# TZ10xx register map
File version: 0.1g
Registers are 32-bit, read-write, reset 0x0 unless marked. A register's access mark holds for its fields unless they carry their own. Offsets are from the block's base; [hi:lo] are bit positions.

## tmr
Base 0x40042000
0x00 TIMER0LOAD
  [31:0] Load — Initial or reload value of the counter (0x00000001 to 0xFFFFFFFF settable) The 0x00000000 setting does not operate the counter. Setting any numeric value other than that enables counting. (Note) Writing to this register writes the same value to Timer0BGLoad.
0x04 TIMER0VALUE ro reset 0xFFFFFFFF — Timer0 Current value Register
  [31:0] value — Count value of the counter at the current time
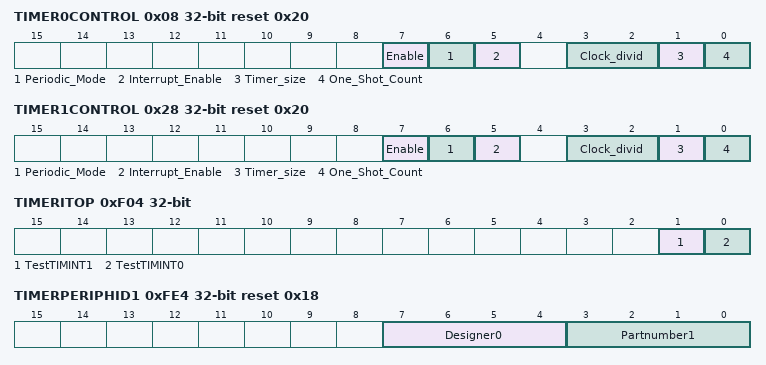
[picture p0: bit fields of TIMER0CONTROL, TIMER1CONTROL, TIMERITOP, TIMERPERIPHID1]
0x08 TIMER0CONTROL reset 0x20
  [7] Enable — Timer operation control 1: Enable 0: Disable
  [6] Periodic_Mode — Timer operation mode 1: Periodic Timer (periodic timer) 0: Free-run Timer (free-run timer)
  [5] Interrupt_Enable — Interrupt control 1: Interrupt enable 0: Interrupt disable
  [3:2] Clock_divid — Prescaler (clock frequency division) 0x3: Reserved 0x2: 1/256 frequency division 0x1: 1/16 frequency division 0x0: No frequency division (same magnification)
  [1] Timer_size — Timer size selection 0x1: Operation as a 32-bit timer 0x0: Operation as a 16-bit timer (high-order bits not used)
  [0] One_Shot_Count — Timer wrapping/one-shot selection 1: One-shot (only one time) 0: Wrapping (repetition)
0x0C TIMER0INTCLR — Timer0 Interrupt clear Register
  [31:0] IntClr — Interrupt clear After the TIMINT0 interrupt occurs, it can be cleared by write access to this register.
0x10 TIMER0RIS ro — Timer0 Raw Interrupt Status Register
  [0] RIS — A timer interrupt (TIMINT0) before masking is occurring. (The interrupt occurs when the counter becomes 0x00000000.) 1: Interrupt request available 0: No interrupt request
0x14 TIMER0MIS ro — Timer0 Masked Interrupt Status Register
  [0] MIS — A timer interrupt (TIMINT0) after masking is occurring. 1: Interrupt request available 0: No interrupt request
0x18 TIMER0BGLOAD — Timer0 BackGround Load Register
  [31:0] BGLoad — Background Load register A count value set in this register is reloaded after the counter becomes 0x00000000 (terminal count). The count value to be reloaded can be changed safely during counting. (Note) Writing to this register does not allow writing to Timer0Load.
0x20 TIMER1LOAD
  [31:0] Load — Initial or reload value of the counter
0x24 TIMER1VALUE ro reset 0xFFFFFFFF — Timer1 Current value Register
  [31:0] value — Count value of the counter at the current time
0x28 TIMER1CONTROL reset 0x20
  [7] Enable — Timer operation control
  [6] Periodic_Mode — Timer operation mode
  [5] Interrupt_Enable — Interrupt control
  [3:2] Clock_divid — Prescaler (clock frequency division)
  [1] Timer_size — Timer size selection
  [0] One_Shot_Count — Selection of timer wrapping and one-shot
0x2C TIMER1INTCLR — Timer1 Interrupt clear Register
  [31:0] IntClr — Interrupt clear
0x30 TIMER1RIS ro — Timer1 Raw Interrupt Status Register
  [0] RIS — A timer interrupt (TIMINT1) after masking is occurring. (The interrupt occurs when the counter becomes 0x00000000.)
0x34 TIMER1MIS ro — Timer1 Masked Interrupt Status Register
  [0] MIS — A timer interrupt (TIMINT1) after masking is occurring.
0x38 TIMER1BGLOAD — Timer1 BackGround Load Register
  [31:0] BGLoad — Background load register
0xF00 TIMERITCR — Timer Integration test control Register
  [0] Test_Mode_Enable — Test mode control 1: Test mode status 0: Normal operation status
0xF04 TIMERITOP — Timer Integration test output set Register
  [1] TestTIMINT1 — Outputs the TIMINT1 signal (only in test mode, write-only) 1: TIMINT1="1" 0: TIMINT1="0" If this register is read, the TMR_TIMERITCR value appears.
  [0] TestTIMINT0 — Outputs the TIMINT0 signal (only in test mode, write-only) 1: TIMINT0="1" 0: TIMINT0="0" If this register is read, the TMR_TIMERITCR value appears.
0xFE0 TIMERPERIPHID0 ro reset 0x4 — Timer Peripheral ID0 Register
  [7:0] Partnumber0 — Peripheral ID (this register stores a value from a hardware viewpoint.) Partnumber(Lower) 804=>04
0xFE4 TIMERPERIPHID1 ro reset 0x18 — Timer Peripheral ID1 Register
  [7:4] Designer0 — Peripheral ID (this register stores a value from a hardware viewpoint.) Designer(Lower) 41=>1
  [3:0] Partnumber1 — Peripheral ID (this register stores a value from a hardware viewpoint.) Partnumber(Lower) 804=>8
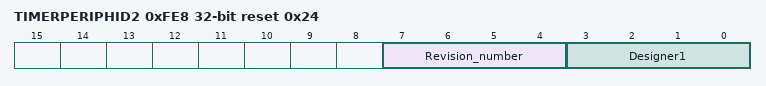
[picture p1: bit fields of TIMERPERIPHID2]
0xFE8 TIMERPERIPHID2 ro reset 0x24 — Timer Peripheral ID2 Register
  [7:4] Revision_number — Peripheral ID (this register stores a value from a hardware viewpoint.) Revision: 1st=>1
  [3:0] Designer1 — Peripheral ID (this register stores a value from a hardware viewpoint.) Designer(Upper) 41=>4
0xFEC TIMERPERIPHID3 ro — Timer Peripheral ID3 Register
  [7:0] Configuration — Peripheral ID (this register stores a value from a hardware viewpoint.) Configuration: 00
0xFF0 TIMERPCELLID0 ro reset 0xD — Timer PrimeCell ID0 Register
  [7:0] TimerPCellID0 — Peripheral ID (this register stores a value from a hardware viewpoint.)
0xFF4 TIMERPCELLID1 ro reset 0xF0 — Timer PrimeCell ID1 Register
  [7:0] TimerPCellID1 — Peripheral ID (this register stores a value from a hardware viewpoint.)
0xFF8 TIMERPCELLID2 ro reset 0x5 — Timer PrimeCell ID2 Register
  [7:0] TimerPCellID2 — Peripheral ID (this register stores a value from a hardware viewpoint.)
0xFFC TIMERPCELLID3 ro reset 0xB1 — Timer PrimeCell ID3 Register
  [7:0] TimerPCellID3 — Peripheral ID (this register stores a value from a hardware viewpoint.)
